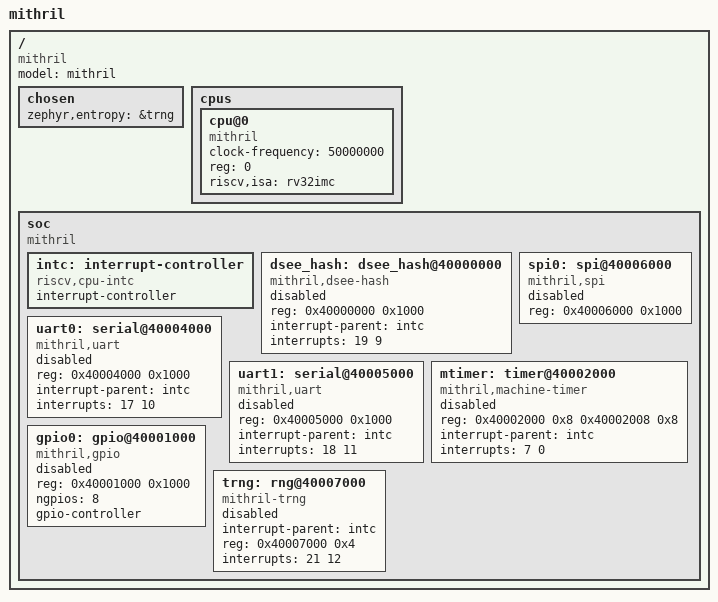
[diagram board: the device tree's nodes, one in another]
/*
 * Copyright (c) 2025 Yusuf Yamak <yamakyusuf@gmail.com>
 *
 * SPDX-License-Identifier: Apache-2.0
 */

/ {
	#address-cells = <1>;
	#size-cells = <1>;
	compatible = "mithril";
	model = "mithril";
	chosen {
		zephyr,entropy = &trng;
	};

	cpus {
		#address-cells = <1>;
		#size-cells = <0>;
		cpu@0 {
			clock-frequency = <50000000>;
			compatible = "mithril", "riscv";
			device_type = "cpu";
			reg = <0>;
			riscv,isa = "rv32imc";
			status = "okay";
		};
	};
	soc {
		#address-cells = <1>;
		#size-cells = <1>;
		compatible = "mithril";
		ranges;

		intc: interrupt-controller {
				compatible = "riscv,cpu-intc";
				#address-cells = <0>;
				#interrupt-cells = <1>;
				interrupt-controller;
				status = "okay";
		};
		
		dsee_hash: dsee_hash@40000000 {
			compatible = "mithril,dsee-hash";
			reg = <0x40000000 0x1000>;
			interrupt-parent = <&intc>;
			interrupts = <19 9>;
			status = "disabled";
		};
		uart0: serial@40004000 {
			compatible = "mithril,uart";
			reg = < 0x40004000 0x1000>;
			interrupt-parent = <&intc>;
			interrupts = <17 10>;
			status = "disabled";
		};

		uart1: serial@40005000 {
			compatible = "mithril,uart";
			reg = < 0x40005000 0x1000>;
			interrupt-parent = <&intc>;
			interrupts = <18 11>;
			status = "disabled";
		};

		spi0: spi@40006000 {
			compatible = "mithril,spi";
			reg = < 0x40006000 0x1000>;
			status = "disabled";
			#address-cells = <1>;
			#size-cells = <0>;
		};

		mtimer: timer@40002000 {
			compatible = "mithril,machine-timer";
			reg = <0x40002000 0x8 0x40002008 0x8>;
			reg-names = "mtime", "mtimecmp";
			interrupt-parent = <&intc>;
			interrupts = <7 0>;
			status = "disabled";
		};

		gpio0: gpio@40001000 {
			compatible = "mithril,gpio";
			reg = < 0x40001000 0x1000>;
			ngpios = <8>;
			gpio-controller;
			status = "disabled";
			#gpio-cells = <2>;
		};

		trng: rng@40007000 {
			compatible = "mithril-trng";
			interrupt-parent = <&intc>;
			reg = <0x40007000 0x4>;
			status = "disabled";
			interrupts = <21 12>;
		};
	};
};
